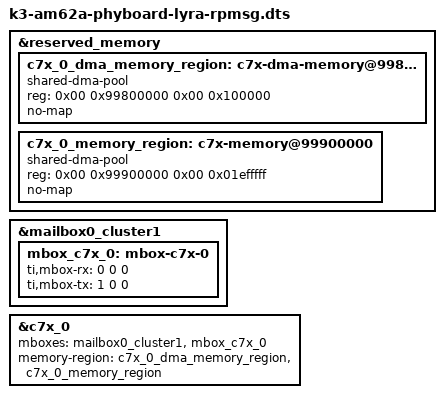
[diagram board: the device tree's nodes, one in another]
// SPDX-License-Identifier: GPL-2.0
/*
 * Copyright (C) 2022 PHYTEC America LLC
 * Author: Garrett Giordano <ggiordano@phytec.com>
 */

/dts-v1/;
/plugin/;

&reserved_memory {
	#address-cells = <2>;
	#size-cells = <2>;

	c7x_0_dma_memory_region: c7x-dma-memory@99800000 {
		compatible = "shared-dma-pool";
		reg = <0x00 0x99800000 0x00 0x100000>;
		no-map;
	};

	c7x_0_memory_region: c7x-memory@99900000 {
		compatible = "shared-dma-pool";
		reg = <0x00 0x99900000 0x00 0x01efffff>;
		no-map;
	};
};

&mailbox0_cluster1 {
	status = "okay";
	mbox_c7x_0: mbox-c7x-0 {
		ti,mbox-rx = <0 0 0>;
		ti,mbox-tx = <1 0 0>;
	};
};

&c7x_0 {
	status = "okay";
	mboxes = <&mailbox0_cluster1 &mbox_c7x_0>;
	memory-region = <&c7x_0_dma_memory_region>,
			<&c7x_0_memory_region>;
};
